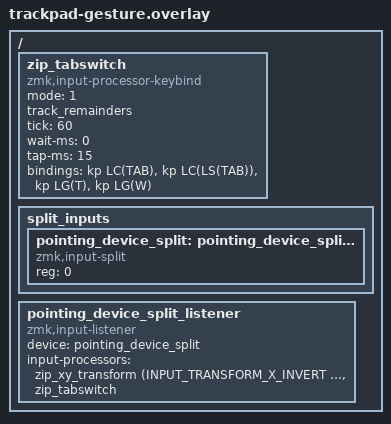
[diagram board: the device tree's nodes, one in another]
#include <input/processors.dtsi>
#include <dt-bindings/zmk/input_transform.h>
#include <dt-bindings/zmk/keys.h>

/*
 * Mini trackpad (left, relayed over zmk,input-split): always-on 4-way swipe
 * gestures for browser tab control, instead of the usual pointer/scroll
 * runtime-input-processor. This is a dedicated snippet (not
 * input-split-listener, which double_ball still uses for a second
 * trackball's pointer/scroll) precisely because gesture-keybind and
 * pointer/scroll are mutually exclusive uses of the same raw XY stream.
 *
 * Axis-to-slot mapping was taken from the module's C source, not its
 * README example (the two disagree on the Y axis):
 *   delta_x > 0 (swipe right) -> bindings[0]
 *   delta_x < 0 (swipe left)  -> bindings[1]
 *   delta_y < 0 (swipe down)  -> bindings[2]
 *   delta_y > 0 (swipe up)    -> bindings[3]
 * The module is explicitly still under development ("somewhat works"), so
 * verify on real hardware; if up/down come out swapped, swap bindings[2]
 * and bindings[3] below. Sensitivity (tick/wait-ms/tap-ms) is compile-time
 * only here - this module doesn't speak Custom Studio Protocol, so it isn't
 * adjustable from DYA Studio like the trackball's runtime input processor.
 */
/ {
    zip_tabswitch: zip_tabswitch {
        compatible = "zmk,input-processor-keybind";
        #input-processor-cells = <0>;
        mode = <1>;
        track_remainders;
        tick = <60>;
        wait-ms = <0>;
        tap-ms = <15>;
        bindings = <&kp LC(TAB)>,      // swipe right -> next tab (Ctrl+Tab)
                    <&kp LC(LS(TAB))>, // swipe left  -> previous tab (Ctrl+Shift+Tab)
                    <&kp LG(T)>,       // swipe down  -> new tab (Cmd+T)
                    <&kp LG(W)>;       // swipe up    -> close tab (Cmd+W)
    };

    split_inputs {
        #address-cells = <1>;
        #size-cells = <0>;

        pointing_device_split: pointing_device_split@0 {
            compatible = "zmk,input-split";
            reg = <0>;
        };
    };

    pointing_device_split_listener: pointing_device_split_listener {
        compatible = "zmk,input-listener";
        device = <&pointing_device_split>;
        status = "okay";
        input-processors = <&zip_xy_transform (INPUT_TRANSFORM_X_INVERT | INPUT_TRANSFORM_Y_INVERT)>, <&zip_tabswitch>;
    };
};
